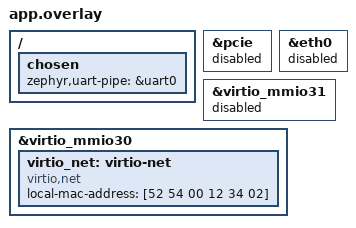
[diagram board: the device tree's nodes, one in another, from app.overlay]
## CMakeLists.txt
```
cmake_minimum_required(VERSION 3.20.0)
find_package(Zephyr REQUIRED HINTS $ENV{ZEPHYR_BASE})
project(zephyr_task2_net)
target_sources(app PRIVATE src/main.c src/periodic.c src/console.c src/telemetry.c)

target_compile_definitions(app PRIVATE RT_START_GATED=1 RT_DUMP_GATED=1)

if(DEFINED RT_SAMPLE_COUNT)
  target_compile_definitions(app PRIVATE RT_SAMPLE_COUNT=${RT_SAMPLE_COUNT})
endif()
```

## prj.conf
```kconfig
CONFIG_NETWORKING=y
CONFIG_ARMV8_A_NS=y
CONFIG_NET_IPV4=y
CONFIG_NET_IPV6=n
CONFIG_NET_UDP=y
CONFIG_NET_SOCKETS=y
CONFIG_NET_CONFIG_SETTINGS=y
CONFIG_NET_CONFIG_AUTO_INIT=n
# QEMU networking is a mandatory Kconfig choice for this generic board, but
# SLIP_TAP must stay off: virtio-net is the data path and the Task-1 gate owns
# console RX (`g`/`d`).
CONFIG_NET_QEMU_SLIP=y
CONFIG_NET_SLIP_TAP=n
CONFIG_NET_L2_ETHERNET=y
CONFIG_NET_CONFIG_MY_IPV4_ADDR="10.0.42.2"
CONFIG_NET_CONFIG_MY_IPV4_NETMASK="255.255.255.0"
CONFIG_NET_CONFIG_PEER_IPV4_ADDR="10.0.42.15"
CONFIG_ETH_VIRTIO_NET=y
CONFIG_ETH_VIRTIO_NET_RX_BUFFERS=1
CONFIG_ETH_NET_IF_NO_AUTO_START=y
CONFIG_VIRTIO=y
CONFIG_VIRTIO_MMIO=y
# The periodic CSV dump and the T2N1 endpoint share one UART. Route all
# application output through printk's global spinlock; the independent log
# backend could otherwise splice a heartbeat into a CSV row.
CONFIG_LOG=n
CONFIG_PRINTK_SYNC=y
CONFIG_ENTROPY_GENERATOR=y
CONFIG_TEST_RANDOM_GENERATOR=y
CONFIG_MAIN_STACK_SIZE=8192
CONFIG_HEAP_MEM_POOL_SIZE=65536
CONFIG_KERNEL_VM_OFFSET=0
CONFIG_KERNEL_VM_SIZE=0x08000000
CONFIG_SERIAL=y
CONFIG_CONSOLE=y
CONFIG_UART_CONSOLE=y
CONFIG_PRINTK=y
CONFIG_SYS_CLOCK_TICKS_PER_SEC=1000
```

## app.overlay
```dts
/* The board's generic PCIe node is not part of this MMIO-only Guest.  Disable
 * both the host controller and its E1000 child; this also prevents the board
 * Kconfig from selecting PCIe support for the image. */
/ {
	chosen {
		zephyr,uart-pipe = &uart0;
	};
};

&pcie {
	status = "disabled";
};

&eth0 {
	status = "disabled";
};

/* Zephyr 4.x's qemu_cortex_a53 board already declares the 32 QEMU
 * virtio-mmio windows.  The socket-pair topology uses slot 30 (GIC SPI 46). */
&virtio_mmio31 {
	status = "disabled";
};

&virtio_mmio30 {
	status = "okay";

	virtio_net: virtio-net {
		compatible = "virtio,net";
		status = "okay";
		local-mac-address = [52 54 00 12 34 02];
	};
};
```

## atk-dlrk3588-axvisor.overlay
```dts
/*
 * AxVisor exposes the RK3588 GIC register windows to this virtualized Guest.
 * The PL011 console and slot-0 virtio-mmio device remain at their QEMU-virt
 * guest addresses because AxVisor creates both as virtual devices.
 */

&gic {
	reg = <0x0 0xfe600000 0x0 0x10000>,
	      <0x0 0xfe680000 0x0 0x100000>;
};

&its {
	status = "disabled";
};
```

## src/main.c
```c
/*
 * Zephyr T2N1 managed endpoint for the task-2 dual-Guest experiment.
 *
 * The wire format intentionally mirrors components/task2-net-protocol.  This
 * adapter owns only UDP and the endpoint state; the virtio driver and network
 * stack remain Zephyr responsibilities.
 */

#include <errno.h>
#include <stdbool.h>
#include <stdint.h>
#include <stdio.h>
#include <string.h>

#include <zephyr/kernel.h>
#include <zephyr/net/net_if.h>
#include <zephyr/net/net_ip.h>
#include <zephyr/net/socket.h>

#include "console.h"
#include "telemetry.h"

#define printk(...) task2_console_trace_printf(__VA_ARGS__)

#define UDP_PORT 4242
#define SESSION_ID UINT32_C(0x54525432)
#define FRAME_HEADER_LEN 28
#define MAX_PAYLOAD_LEN 1200
#define MAX_DATAGRAM_LEN (FRAME_HEADER_LEN + MAX_PAYLOAD_LEN)
#define RETRANSMIT_AFTER_MS 500
#define MAX_RETRIES 5
#define HEARTBEAT_INTERVAL_MS 200
#define PEER_TIMEOUT_MS 10000

#ifndef TASK2_FAULT_DROP_ACK_MODE
#define TASK2_FAULT_DROP_ACK_MODE 0
#endif

/*
 * Task-3 virtual plant: a nonlinear thermal-like object in 0..1000.
 *
 *   loss(state) = base_loss + nonlinear_loss * state^2 / 1_000_000
 *   state_next  = clamp(state + response * (output - state)
 *                       - loss(state) + disturbance, 0, 1000)
 *
 * The plant runs inside the RTOS Guest; the Linux side only observes it
 * through the T2N1 STATUS value.  Parameters are frozen (see
 * book/design/task3-ai-control-todo.md M0) and must not be tuned after
 * baseline/AI comparison runs start.
 */
#define PLANT_STATE_MIN 0
#define PLANT_STATE_MAX 1000
#define PLANT_BASE_LOSS 15
#define PLANT_NONLINEAR_LOSS 120
#define PLANT_RESPONSE 350
#define PLANT_RESPONSE_DEN 1000
#define PLANT_DISTURBANCE_MAX 150

static int32_t plant_state = 300;
static int32_t plant_disturbance = 0;

static int task2_configure_network(void)
{
	struct net_if *iface = net_if_get_default();
	struct net_in_addr local;
	struct net_in_addr netmask;

	if (iface == NULL || net_addr_pton(NET_AF_INET, "10.0.42.2", &local) != 0 ||
	    net_addr_pton(NET_AF_INET, "255.255.255.0", &netmask) != 0) {
		return -EINVAL;
	}

	if (net_if_ipv4_addr_add(iface, &local, NET_ADDR_MANUAL, 0) == NULL ||
	    !net_if_ipv4_set_netmask_by_addr(iface, &local, &netmask)) {
		return -EINVAL;
	}

	int status = net_if_up(iface);
	return status < 0 && status != -EALREADY ? status : 0;
}

enum message_kind {
	KIND_CONTROL = 1,
	KIND_STATUS = 2,
	KIND_ERROR = 3,
	KIND_ACK = 4,
	KIND_HEARTBEAT = 5,
};

enum error_code {
	ERROR_INVALID_PARAMETER = 1,
	ERROR_OUT_OF_ORDER = 2,
	ERROR_UNSUPPORTED_MESSAGE = 3,
	ERROR_SESSION_MISMATCH = 4,
};

static uint32_t read_u32(const uint8_t *bytes)
{
	return ((uint32_t)bytes[0] << 24) | ((uint32_t)bytes[1] << 16) |
	       ((uint32_t)bytes[2] << 8) | bytes[3];
}

static uint16_t read_u16(const uint8_t *bytes)
{
	return (uint16_t)(((uint16_t)bytes[0] << 8) | bytes[1]);
}

static void write_u32(uint8_t *bytes, uint32_t value)
{
	bytes[0] = (uint8_t)(value >> 24);
	bytes[1] = (uint8_t)(value >> 16);
	bytes[2] = (uint8_t)(value >> 8);
	bytes[3] = (uint8_t)value;
}

static void write_u16(uint8_t *bytes, uint16_t value)
{
	bytes[0] = (uint8_t)(value >> 8);
	bytes[1] = (uint8_t)value;
}

static uint32_t crc32_update(uint32_t crc, const uint8_t *bytes, size_t length)
{
	for (size_t index = 0; index < length; index++) {
		crc ^= bytes[index];
		for (unsigned bit = 0; bit < 8; bit++) {
			crc = (crc >> 1) ^ (UINT32_C(0xedb88320) & (-(int32_t)(crc & 1)));
		}
	}
	return crc;
}

static uint32_t frame_crc(const uint8_t *frame, size_t length)
{
	uint32_t crc = UINT32_MAX;

	crc = crc32_update(crc, frame, 24);
	uint8_t zero_checksum[4] = {0};
	crc = crc32_update(crc, zero_checksum, sizeof(zero_checksum));
	crc = crc32_update(crc, frame + 28, length - 28);
	return ~crc;
}

static size_t encode_frame(uint8_t *output, uint8_t kind, uint16_t flags,
				   uint32_t sequence, uint32_t acknowledgement,
				   uint16_t error, const uint8_t *payload, size_t payload_len)
{
	if (payload_len > MAX_PAYLOAD_LEN) {
		return 0;
	}
	memset(output, 0, FRAME_HEADER_LEN + payload_len);
	memcpy(output, "T2N1", 4);
	output[4] = 1;
	output[5] = kind;
	write_u16(output + 6, flags);
	write_u32(output + 8, SESSION_ID);
	write_u32(output + 12, sequence);
	write_u32(output + 16, acknowledgement);
	write_u16(output + 20, (uint16_t)payload_len);
	write_u16(output + 22, error);
	if (payload_len > 0) {
		memcpy(output + FRAME_HEADER_LEN, payload, payload_len);
	}
	write_u32(output + 24, frame_crc(output, FRAME_HEADER_LEN + payload_len));
	return FRAME_HEADER_LEN + payload_len;
}

static int parse_frame(const uint8_t *frame, size_t length, uint8_t *kind,
			       uint16_t *flags, uint32_t *sequence,
			       uint32_t *acknowledgement, uint16_t *error,
			       uint32_t *session_id, const uint8_t **payload,
			       size_t *payload_len)
{
	if (length < FRAME_HEADER_LEN || memcmp(frame, "T2N1", 4) != 0 || frame[4] != 1) {
		return -EINVAL;
	}
	*kind = frame[5];
	*flags = read_u16(frame + 6);
	*session_id = read_u32(frame + 8);
	*sequence = read_u32(frame + 12);
	*acknowledgement = read_u32(frame + 16);
	*payload_len = read_u16(frame + 20);
	*error = read_u16(frame + 22);
	if ((*flags & ~UINT16_C(1)) != 0 || *payload_len > MAX_PAYLOAD_LEN ||
	    *payload_len != length - FRAME_HEADER_LEN ||
	    read_u32(frame + 24) != frame_crc(frame, length)) {
		return -EINVAL;
	}
	*payload = frame + FRAME_HEADER_LEN;
	if ((*kind == KIND_CONTROL || *kind == KIND_STATUS) &&
	    (*flags != 1 || *sequence == 0 || *acknowledgement != 0 || *error != 0)) {
		return -EINVAL;
	}
	if (*kind == KIND_ACK &&
	    (*flags != 0 || *sequence != 0 || *acknowledgement == 0 || *error != 0 ||
	     *payload_len != 0)) {
		return -EINVAL;
	}
	/* ERROR frames correlate a reliable request through acknowledgement.  An
	 * unsequenced HEARTBEAT has no request sequence, so its ERROR is allowed
	 * to carry acknowledgement 0; reliable-frame errors still carry the
	 * rejected sequence in acknowledgement. */
	if (*kind == KIND_ERROR &&
	    (*flags != 0 || *sequence != 0 || *error == 0 ||
	     *error > ERROR_SESSION_MISMATCH)) {
		return -EINVAL;
	}
	if (*kind == KIND_HEARTBEAT &&
	    (*flags != 0 || *sequence != 0 || *acknowledgement != 0 || *error != 0)) {
		return -EINVAL;
	}
	if (*kind < KIND_CONTROL || *kind > KIND_HEARTBEAT) {
		return -EINVAL;
	}
	return 0;
}

static bool valid_control(const uint8_t *payload, size_t length)
{
	if (length != 12 || payload[1] != 0 || payload[2] != 0 || payload[3] != 0) {
		return false;
	}
	uint8_t action = payload[0];
	int32_t value = (int32_t)read_u32(payload + 4);
	if (action == 1) {
		return value >= 0 && value <= 1000;
	}
	return (action == 2 || action == 3) && value == 0;
}

static bool valid_status(const uint8_t *payload, size_t length)
{
	return length == 12 && payload[0] >= 1 && payload[0] <= 3 &&
	       (payload[1] & ~UINT8_C(3)) == 0 && payload[2] == 0 && payload[3] == 0;
}

static bool valid_heartbeat(const uint8_t *payload, size_t length)
{
	return length == 8;
}

static bool send_frame(int socket, const struct sockaddr_in *peer, uint8_t *frame,
			       size_t length, const char *operation)
{
	int sent = zsock_sendto(socket, frame, length, 0, (const struct sockaddr *)peer,
				sizeof(*peer));
	if (sent == (int)length) {
		return true;
	}
	printk("TASK2_SAFE state=Safe event=SendFailure operation=%s sent=%d expected=%u "
	       "errno=%d\n",
	       operation, sent, (unsigned)length, errno);
	return false;
}

static bool same_peer(const struct sockaddr_in *source, const struct sockaddr_in *peer)
{
	return source->sin_family == peer->sin_family && source->sin_port == peer->sin_port &&
	       source->sin_addr.s_addr == peer->sin_addr.s_addr;
}

static size_t make_ack(uint8_t *frame, uint32_t sequence)
{
	return encode_frame(frame, KIND_ACK, 0, 0, sequence, 0, NULL, 0);
}

static size_t make_error(uint8_t *frame, uint32_t sequence, uint16_t error)
{
	return encode_frame(frame, KIND_ERROR, 0, 0, sequence, error, NULL, 0);
}

static size_t make_heartbeat(uint8_t *frame, uint64_t uptime_ms)
{
	uint8_t payload[8];
	for (unsigned index = 0; index < 8; index++) {
		payload[7 - index] = (uint8_t)(uptime_ms >> (index * 8));
	}
	return encode_frame(frame, KIND_HEARTBEAT, 0, 0, 0, 0, payload, sizeof(payload));
}

/*
 * Fixed disturbance schedule (frozen in M0):
 *   8 s  after boot: +150 load step
 *   17 s after boot: -150 load step
 */
static void plant_update_disturbance(int64_t now_ms)
{
	int64_t scheduled = 0;

	if (now_ms >= 8000 && now_ms < 17000) {
		scheduled = PLANT_DISTURBANCE_MAX;
	} else if (now_ms >= 17000) {
		scheduled = 0;
	}
	if (scheduled != plant_disturbance) {
		plant_disturbance = scheduled;
		printk("TASK3_DISTURBANCE change=%d at_ms=%lld\n", (int)scheduled, (long long)now_ms);
	}
}

static int32_t plant_update(int32_t output)
{
	int64_t loss = PLANT_BASE_LOSS +
		       (int64_t)PLANT_NONLINEAR_LOSS * plant_state * plant_state / 1000000;
	int64_t response = (int64_t)PLANT_RESPONSE * (output - plant_state) / PLANT_RESPONSE_DEN;
	int64_t next = plant_state + response - loss + plant_disturbance;

	if (next < PLANT_STATE_MIN) {
		next = PLANT_STATE_MIN;
	} else if (next > PLANT_STATE_MAX) {
		next = PLANT_STATE_MAX;
	}
	plant_state = (int32_t)next;
	return plant_state;
}

int main(void)
{
	struct sockaddr_in local = {0};
	struct sockaddr_in peer = {0};
	uint8_t inbound[MAX_DATAGRAM_LEN];
	uint8_t outbound[MAX_DATAGRAM_LEN];
	uint8_t pending_frame[MAX_DATAGRAM_LEN];
	size_t pending_length = 0;
	uint32_t next_tx_sequence = 1;
	uint32_t expected_rx_sequence = 1;
	uint32_t last_acknowledged = 0;
	uint32_t pending_sequence = 0;
	uint8_t retry_count = 0;
	int drop_control_ack_mode = TASK2_FAULT_DROP_ACK_MODE;
	uint32_t dropped_ack_sequence = 0;
	bool dropped_ack_duplicate_seen = false;
	int state_safe = 0;
	uint8_t managed_state = 1;
	int socket;
	int64_t now;
	int64_t last_rx = k_uptime_get();
	int64_t last_tx = last_rx;
	int64_t pending_sent = last_rx;

	printk("TASK2_MAIN_START\n");
	if (task2_configure_network() != 0) {
		printk("TASK2_ERROR network configuration failed\n");
		return 1;
	}
	local.sin_family = AF_INET;
	local.sin_port = htons(UDP_PORT);
	local.sin_addr.s_addr = htonl(INADDR_ANY);
	peer.sin_family = AF_INET;
	peer.sin_port = htons(UDP_PORT);
	if (zsock_inet_pton(AF_INET, "10.0.42.15", &peer.sin_addr) != 1) {
		printk("TASK2_ERROR invalid peer address\n");
		return 1;
	}
	printk("TASK2_SOCKET_CREATE\n");
	socket = zsock_socket(AF_INET, SOCK_DGRAM, IPPROTO_UDP);
	printk("TASK2_SOCKET_CREATED fd=%d\n", socket);
	if (socket < 0 || zsock_bind(socket, (struct sockaddr *)&local, sizeof(local)) < 0) {
		printk("TASK2_ERROR UDP bind errno=%d\n", errno);
		return 1;
	}
	printk("TASK2_NET_CONFIGURED interface=virtio-net ip=10.0.42.2/24\n");
	printk("TASK2_READY role=managed local=10.0.42.2:4242 peer=10.0.42.15:4242\n");
	if (drop_control_ack_mode == 1) {
		printk("TASK2_FAULT_MODE mode=drop-ack-once\n");
	} else if (drop_control_ack_mode == 2) {
		printk("TASK2_FAULT_MODE mode=drop-ack-always\n");
	}

	for (;;) {
		struct zsock_pollfd pollfd = {.fd = socket, .events = ZSOCK_POLLIN};
		int poll_result = zsock_poll(&pollfd, 1, 100);
		now = k_uptime_get();
		if (poll_result > 0 && (pollfd.revents & ZSOCK_POLLIN) != 0) {
			struct sockaddr_in source;
			socklen_t source_length = sizeof(source);
			ssize_t received = zsock_recvfrom(socket, inbound, sizeof(inbound), 0,
							(struct sockaddr *)&source, &source_length);
			uint8_t kind;
			uint16_t flags, error;
			uint32_t session_id, sequence, acknowledgement;
			const uint8_t *payload;
			size_t payload_length;
			if (received < 0) {
				printk("TASK2_REJECTED receive_error errno=%d\n", errno);
			} else if (!same_peer(&source, &peer)) {
				printk("TASK2_REJECTED unexpected_source\n");
			} else if (parse_frame(inbound, (size_t)received, &kind, &flags,
						       &sequence, &acknowledgement, &error, &session_id,
						       &payload, &payload_length) != 0) {
				printk("TASK2_REJECTED malformed_frame\n");
			} else if (session_id != SESSION_ID) {
				/* Session identity is a semantic protocol error, not a malformed
				 * datagram.  Heartbeats are unsequenced, so their ERROR carries
				 * acknowledgement 0; reliable frames carry the rejected sequence. */
				size_t error_length = make_error(outbound, sequence,
								ERROR_SESSION_MISMATCH);
				if (!send_frame(socket, &source, outbound, error_length, "session-error")) {
					return 1;
				}
				printk("TASK2_SESSION_MISMATCH peer_session=0x%08x ack=%u\n",
				       session_id, sequence);
			} else {
				last_rx = now;
				int was_safe = state_safe;
				state_safe = 0;
				if (was_safe) {
					/* Mirror the Rust endpoint's recovery resync: after a
					 * data-link outage both sides restart the reliable
					 * stream from sequence 1.  Otherwise a lost STATUS
					 * (the peer advanced to n+1 while we still expect n)
					 * loops on OutOfOrder forever after recovery. */
					next_tx_sequence = 1;
					expected_rx_sequence = 1;
					last_acknowledged = 0;
					pending_sequence = 0;
					pending_length = 0;
					retry_count = 0;
				}
				if (kind == KIND_ACK) {
					if (pending_length > 0 && acknowledgement == pending_sequence) {
						pending_length = 0;
						last_acknowledged = acknowledgement;
						printk("TASK2_ACK seq=%u\n", acknowledgement);
					} else if (acknowledgement == last_acknowledged) {
						printk("TASK2_DUPLICATE_ACK seq=%u\n", acknowledgement);
					} else {
						printk("TASK2_REJECTED invalid_ack ack=%u\n", acknowledgement);
					}
				} else if (kind == KIND_ERROR) {
					state_safe = 1;
					printk("TASK2_SAFE state=Safe event=RemoteError code=%u ack=%u\n",
					       error, acknowledgement);
				} else if (kind == KIND_HEARTBEAT) {
					if (!valid_heartbeat(payload, payload_length)) {
						size_t error_length = make_error(outbound, 0,
											ERROR_INVALID_PARAMETER);
						if (!send_frame(socket, &source, outbound, error_length,
								"heartbeat-error")) {
							return 1;
						}
						state_safe = 1;
						printk("TASK2_SAFE state=Safe event=InvalidParameter\n");
					} else {
						uint64_t uptime = 0;
						for (unsigned index = 0; index < 8; index++) {
							uptime = (uptime << 8) | payload[index];
						}
						task2_telemetry_note_heartbeat();
						printk("TASK2_HEARTBEAT_RECEIVED peer_uptime_ms=%llu\n", uptime);
					}
				} else if (kind == KIND_CONTROL || kind == KIND_STATUS) {
					bool valid = kind == KIND_CONTROL ? valid_control(payload, payload_length)
											 : valid_status(payload, payload_length);
					if (!valid) {
						size_t error_length = make_error(outbound, sequence,
											ERROR_INVALID_PARAMETER);
						if (!send_frame(socket, &source, outbound, error_length,
								"payload-error")) {
							return 1;
						}
						state_safe = 1;
						printk("TASK2_PROTOCOL_ERROR invalid_parameter seq=%u\n", sequence);
					} else if (sequence == expected_rx_sequence) {
						expected_rx_sequence = sequence == UINT32_MAX ? 1 : sequence + 1;
						size_t ack_length = make_ack(outbound, sequence);
						if (kind == KIND_CONTROL && drop_control_ack_mode != 0) {
							if (drop_control_ack_mode == 1) {
								drop_control_ack_mode = 0;
							}
							dropped_ack_sequence = sequence;
							printk("TASK2_FAULT_DROP_ACK%s seq=%u\n",
							       TASK2_FAULT_DROP_ACK_MODE == 2 ? "_ALWAYS" : "",
							       sequence);
						} else {
							if (!send_frame(socket, &source, outbound, ack_length, "ack")) {
								return 1;
							}
						}
						if (kind == KIND_CONTROL) {
						task2_telemetry_note_control();
						uint8_t action = payload[0];
						int32_t output = (int32_t)read_u32(payload + 4);
						uint32_t request = read_u32(payload + 8);
						int32_t state_before = plant_state;

						plant_update_disturbance(now);
						if (action == 1) {
							managed_state = 1;
							/* Bounded values were validated on the wire; retain a
							 * defensive clamp at the plant boundary. */
							plant_update(output < PLANT_STATE_MIN ? PLANT_STATE_MIN :
								       output > PLANT_STATE_MAX ? PLANT_STATE_MAX :
								       output);
						} else if (action == 2) {
							managed_state = 2;
						} else {
							managed_state = 1;
						}

						uint8_t status_payload[12] = {0};
						status_payload[0] = managed_state;
						write_u32(status_payload + 4, (uint32_t)plant_state);
						write_u32(status_payload + 8, request);
						pending_sequence = next_tx_sequence++;
						if (pending_sequence == 0) {
							pending_sequence = next_tx_sequence++;
						}
						pending_length = encode_frame(pending_frame, KIND_STATUS, 1,
											pending_sequence, 0, 0, status_payload, 12);
						pending_sent = now;
						retry_count = 0;
						if (!send_frame(socket, &source, pending_frame, pending_length,
								"status")) {
							return 1;
						}
						task2_telemetry_note_status();
						last_tx = now;
						printk("TASK2_CONTROL_RECEIVED seq=%u request=%u\n", sequence,
						       request);
						printk("TASK3_CONTROL_APPLIED request=%u value=%d\n", request,
						       output);
						printk("TASK3_PLANT_STATE before=%d after=%d dist=%d\n",
						       state_before, plant_state, plant_disturbance);
						printk("TASK2_STATUS_SENT seq=%u\n", pending_sequence);
						if (dropped_ack_duplicate_seen) {
							printk("TASK2_FAULT_DROP_ACK_RECOVERED duplicate_seq=%u\n",
							       dropped_ack_sequence);
							dropped_ack_duplicate_seen = false;
						}
					}
					} else if (sequence == (expected_rx_sequence == 1 ? UINT32_MAX : expected_rx_sequence - 1)) {
						size_t ack_length = make_ack(outbound, sequence);
						if (kind == KIND_CONTROL && drop_control_ack_mode == 2) {
							printk("TASK2_FAULT_DROP_ACK_ALWAYS seq=%u duplicate=true\n",
							       sequence);
						} else {
							if (!send_frame(socket, &source, outbound, ack_length,
									"duplicate-ack")) {
								return 1;
							}
						}
						if (sequence == dropped_ack_sequence) {
							dropped_ack_duplicate_seen = true;
						}
						printk("TASK2_DUPLICATE seq=%u\n", sequence);
					} else {
						size_t error_length = make_error(outbound, sequence, ERROR_OUT_OF_ORDER);
						if (!send_frame(socket, &source, outbound, error_length,
								"order-error")) {
							return 1;
						}
						state_safe = 1;
						printk("TASK2_PROTOCOL_ERROR out_of_order=%u expected=%u\n", sequence,
						       expected_rx_sequence);
					}
				} else {
					printk("TASK2_REJECTED unsupported_kind=%u\n", kind);
				}
			}
		}

		if (pending_length > 0 && now - pending_sent >= RETRANSMIT_AFTER_MS) {
			if (retry_count >= MAX_RETRIES) {
				pending_length = 0;
				state_safe = 1;
				printk("TASK2_SAFE state=Safe event=RetryExhausted seq=%u\n", pending_sequence);
			} else {
				retry_count++;
				pending_sent = now;
				if (!send_frame(socket, &peer, pending_frame, pending_length,
						"retransmit")) {
					return 1;
				}
				printk("TASK2_RETRANSMIT seq=%u attempt=%u\n", pending_sequence,
				       retry_count);
			}
		}
		if (!state_safe && now - last_rx >= PEER_TIMEOUT_MS) {
			state_safe = 1;
			printk("TASK2_SAFE state=Safe event=HeartbeatTimeout\n");
		}
		if (now - last_tx >= HEARTBEAT_INTERVAL_MS) {
			size_t heartbeat_length = make_heartbeat(outbound, (uint64_t)now);
			if (!send_frame(socket, &peer, outbound, heartbeat_length, "heartbeat")) {
				return 1;
			}
			last_tx = now;
		}
	}
}
```

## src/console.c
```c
#include "console.h"

#include <stdarg.h>

#include <zephyr/kernel.h>
#include <zephyr/sys/atomic.h>
#include <zephyr/sys/printk.h>

#ifndef TASK2_RUNTIME_TRACE
#define TASK2_RUNTIME_TRACE 0
#endif

K_MUTEX_DEFINE(task2_console_mutex);
static atomic_t trace_quiet;

void task2_console_lock(void)
{
	(void)k_mutex_lock(&task2_console_mutex, K_FOREVER);
}

void task2_console_unlock(void)
{
	(void)k_mutex_unlock(&task2_console_mutex);
}

void task2_console_printf_locked(const char *format, ...)
{
	va_list arguments;

	va_start(arguments, format);
	vprintk(format, arguments);
	va_end(arguments);
}

void task2_console_printf(const char *format, ...)
{
	va_list arguments;

	task2_console_lock();
	va_start(arguments, format);
	vprintk(format, arguments);
	va_end(arguments);
	task2_console_unlock();
}

void task2_console_set_trace_quiet(bool quiet)
{
	atomic_set(&trace_quiet, quiet ? 1 : 0);
	/* Drain a trace call which observed the old state before returning. */
	task2_console_lock();
	task2_console_unlock();
}

void task2_console_trace_printf(const char *format, ...)
{
#if TASK2_RUNTIME_TRACE
	va_list arguments;

	if (atomic_get(&trace_quiet) != 0) {
		return;
	}
	task2_console_lock();
	/* Recheck after locking so the quiet transition cannot race this call. */
	if (atomic_get(&trace_quiet) == 0) {
		va_start(arguments, format);
		vprintk(format, arguments);
		va_end(arguments);
	}
	task2_console_unlock();
#else
	ARG_UNUSED(format);
#endif
}
```

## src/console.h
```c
#ifndef TASK2_CONSOLE_H_
#define TASK2_CONSOLE_H_

#include <stdbool.h>

#include <zephyr/toolchain.h>

__printf_like(1, 2) void task2_console_printf(const char *format, ...);
__printf_like(1, 2) void task2_console_trace_printf(const char *format, ...);
void task2_console_set_trace_quiet(bool quiet);
void task2_console_lock(void);
void task2_console_unlock(void);
__printf_like(1, 2) void task2_console_printf_locked(const char *format, ...);

#endif /* TASK2_CONSOLE_H_ */
```

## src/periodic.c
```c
/*
 * Task-1 periodic wake-up probe embedded in the Task-2/3 Zephyr endpoint.
 *
 * The probe is dormant until the board runner sends 'g' to the Zephyr
 * console. It retains samples in RAM and waits for 'd' before exporting
 * them, so UART output cannot perturb the measured interval. The network
 * endpoint in main.c continues to run while this thread samples.
 */

#include <stdint.h>

#include <zephyr/device.h>
#include <zephyr/devicetree.h>
#include <zephyr/drivers/uart.h>
#include <zephyr/kernel.h>
#include <zephyr/sys/time_units.h>

#include "console.h"
#include "telemetry.h"

#define PERIOD_MS 10
#ifndef RT_SAMPLE_COUNT
#define RT_SAMPLE_COUNT 300
#endif
#define SAMPLE_COUNT RT_SAMPLE_COUNT

struct latency_sample {
	int64_t timestamp_ns;
	int64_t deadline_ns;
	int64_t actual_ns;
	int64_t jitter_ns;
};

static struct latency_sample samples[SAMPLE_COUNT];

static int64_t cycles_to_ns(int64_t cycles)
{
	return (int64_t)k_cyc_to_ns_floor64((uint64_t)cycles);
}

static void wait_for_console_byte(unsigned char expected)
{
	const struct device *console = DEVICE_DT_GET(DT_CHOSEN(zephyr_console));
	unsigned char byte = 0;

	while (!device_is_ready(console)) {
		k_sleep(K_MSEC(1));
	}

	while (byte != expected) {
		if (uart_poll_in(console, &byte) != 0) {
			k_sleep(K_MSEC(1));
		}
	}
}

static void capture_samples(void)
{
	const int64_t period_ticks = k_ms_to_ticks_ceil64(PERIOD_MS);
	const int64_t period_cycles =
		(int64_t)sys_clock_hw_cycles_per_sec() * PERIOD_MS / 1000;
	int64_t base_ticks = k_uptime_ticks();

	while (k_uptime_ticks() == base_ticks) {
	}
	base_ticks = k_uptime_ticks();
	const int64_t base_cycles = (int64_t)k_cycle_get_64();

	for (int64_t sequence = 0; sequence < SAMPLE_COUNT; sequence++) {
		const int64_t deadline_ticks = base_ticks + (sequence + 1) * period_ticks;

		k_sleep(K_TIMEOUT_ABS_TICKS(deadline_ticks));

		const int64_t actual_cycles = (int64_t)k_cycle_get_64();
		const int64_t deadline_ns =
			cycles_to_ns(base_cycles + (sequence + 1) * period_cycles);
		const int64_t actual_ns = cycles_to_ns(actual_cycles);
		samples[sequence] = (struct latency_sample) {
			.timestamp_ns = cycles_to_ns(actual_cycles - base_cycles),
			.deadline_ns = deadline_ns,
			.actual_ns = actual_ns,
			.jitter_ns = actual_ns - deadline_ns,
		};
	}
}

static void print_samples(void)
{
	task2_console_lock();
	task2_console_printf_locked("sequence,timestamp_ns,deadline_ns,actual_ns,jitter_ns\n");
	for (int64_t sequence = 0; sequence < SAMPLE_COUNT; sequence++) {
		task2_console_printf_locked("%lld,%lld,%lld,%lld,%lld\n", sequence,
					    samples[sequence].timestamp_ns,
					    samples[sequence].deadline_ns,
					    samples[sequence].actual_ns,
					    samples[sequence].jitter_ns);
	}
	task2_console_printf_locked("PERIODIC LATENCY COMPLETE samples=%d\n", SAMPLE_COUNT);
	task2_console_unlock();
}

static void periodic_probe_thread(void *unused1, void *unused2, void *unused3)
{
	struct task2_telemetry_snapshot telemetry_before;
	struct task2_telemetry_snapshot telemetry_after;

	ARG_UNUSED(unused1);
	ARG_UNUSED(unused2);
	ARG_UNUSED(unused3);

	task2_console_printf(
		"PERIODIC LATENCY READY frequency_hz=%u period_ms=%u samples=%u\n",
		(unsigned int)sys_clock_hw_cycles_per_sec(), PERIOD_MS, SAMPLE_COUNT);
	wait_for_console_byte('g');
	task2_console_printf("PERIODIC LATENCY START\n");
	task2_console_set_trace_quiet(true);
	telemetry_before = task2_telemetry_snapshot();
	capture_samples();
	telemetry_after = task2_telemetry_snapshot();
	task2_console_set_trace_quiet(false);
	task2_console_printf(
		"PERIODIC LATENCY SAMPLING COMPLETE samples=%d controls=%u statuses=%u heartbeats=%u\n",
		SAMPLE_COUNT,
		telemetry_after.controls_received - telemetry_before.controls_received,
		telemetry_after.statuses_sent - telemetry_before.statuses_sent,
		telemetry_after.heartbeats_received - telemetry_before.heartbeats_received);
	wait_for_console_byte('d');
	print_samples();
}

K_THREAD_DEFINE(periodic_probe_thread_id, 2048, periodic_probe_thread, NULL, NULL, NULL,
		0, 0, 0);
```

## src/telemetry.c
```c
#include "telemetry.h"

#include <zephyr/sys/atomic.h>

static atomic_t controls_received;
static atomic_t statuses_sent;
static atomic_t heartbeats_received;

void task2_telemetry_note_control(void)
{
	atomic_inc(&controls_received);
}

void task2_telemetry_note_status(void)
{
	atomic_inc(&statuses_sent);
}

void task2_telemetry_note_heartbeat(void)
{
	atomic_inc(&heartbeats_received);
}

struct task2_telemetry_snapshot task2_telemetry_snapshot(void)
{
	return (struct task2_telemetry_snapshot) {
		.controls_received = (uint32_t)atomic_get(&controls_received),
		.statuses_sent = (uint32_t)atomic_get(&statuses_sent),
		.heartbeats_received = (uint32_t)atomic_get(&heartbeats_received),
	};
}
```

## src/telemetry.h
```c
#ifndef TASK2_TELEMETRY_H_
#define TASK2_TELEMETRY_H_

#include <stdint.h>

struct task2_telemetry_snapshot {
	uint32_t controls_received;
	uint32_t statuses_sent;
	uint32_t heartbeats_received;
};

void task2_telemetry_note_control(void);
void task2_telemetry_note_status(void);
void task2_telemetry_note_heartbeat(void);
struct task2_telemetry_snapshot task2_telemetry_snapshot(void);

#endif /* TASK2_TELEMETRY_H_ */
```
